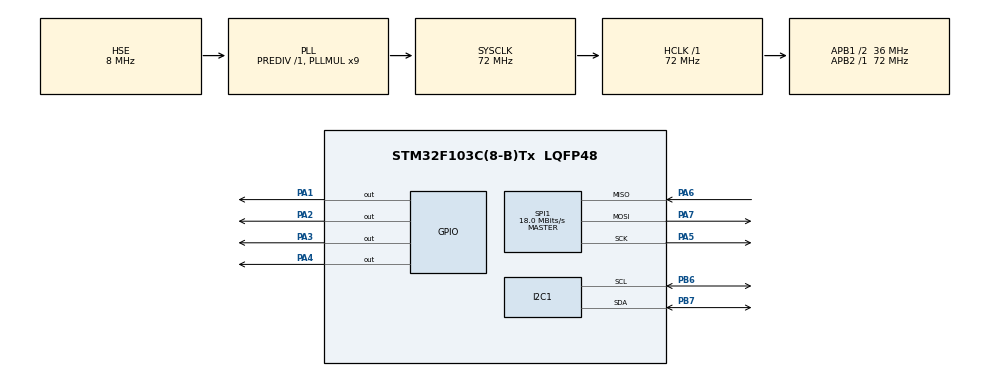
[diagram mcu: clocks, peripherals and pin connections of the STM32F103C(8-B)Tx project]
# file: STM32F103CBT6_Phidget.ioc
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Mcu.Family=STM32F1
Mcu.Name=STM32F103C(8-B)Tx
Mcu.Package=LQFP48
NVIC.I2C1_ER_IRQn=true\:0\:0\:false\:false\:true
NVIC.I2C1_EV_IRQn=true\:0\:0\:false\:false\:true
NVIC.PriorityGroup=NVIC_PRIORITYGROUP_4
NVIC.RCC_IRQn=true\:0\:0\:false\:false\:true
NVIC.RTC_IRQn=true\:0\:0\:false\:false\:true
NVIC.SPI1_IRQn=true\:0\:0\:false\:false\:true
NVIC.TIM1_UP_IRQn=true\:2\:0\:true\:false\:true
NVIC.TIM2_IRQn=true\:2\:0\:true\:false\:true
NVIC.TIM3_IRQn=true\:2\:0\:true\:false\:true
NVIC.TIM4_IRQn=true\:2\:0\:true\:false\:true
PA1.Signal=GPIO_Output
PA13.Mode=Serial_Wire
PA13.Signal=SYS_JTMS-SWDIO
PA14.Mode=Serial_Wire
PA14.Signal=SYS_JTCK-SWCLK
PA2.Signal=GPIO_Output
PA3.Signal=GPIO_Output
PA4.Signal=GPIO_Output
PA5.Mode=Full_Duplex_Master
PA5.Signal=SPI1_SCK
PA6.Mode=Full_Duplex_Master
PA6.Signal=SPI1_MISO
PA7.Mode=Full_Duplex_Master
PA7.Signal=SPI1_MOSI
PB6.Mode=I2C
PB6.Signal=I2C1_SCL
PB7.Mode=I2C
PB7.Signal=I2C1_SDA
PD0-OSC_IN.Mode=HSE-External-Oscillator
PD0-OSC_IN.Signal=RCC_OSC_IN
PD1-OSC_OUT.Mode=HSE-External-Oscillator
PD1-OSC_OUT.Signal=RCC_OSC_OUT
ProjectManager.HeapSize=0x200
ProjectManager.StackSize=0x400
ProjectManager.TargetToolchain=MDK-ARM V5
RCC.AHBFreq_Value=72000000
RCC.APB1CLKDivider=RCC_HCLK_DIV2
RCC.APB1Freq_Value=36000000
RCC.APB1TimFreq_Value=72000000
RCC.APB2Freq_Value=72000000
RCC.APB2TimFreq_Value=72000000
RCC.EnbaleCSS=true
RCC.HCLKFreq_Value=72000000
RCC.HSIState=RCC_HSI_ON
RCC.PLLMUL=RCC_PLL_MUL9
RCC.PLLSourceVirtual=RCC_PLLSOURCE_HSE
RCC.SYSCLKFreq_VALUE=72000000
RCC.SYSCLKSource=RCC_SYSCLKSOURCE_PLLCLK
RCC.USBFreq_Value=72000000
SPI1.BaudRatePrescaler=SPI_BAUDRATEPRESCALER_4
SPI1.CalculateBaudRate=18.0 MBits/s
SPI1.Mode=SPI_MODE_MASTER
TIM1.Period=59999
TIM1.Prescaler=11
TIM2.Period=59999
TIM2.Prescaler=11
TIM3.Period=59999
TIM3.Prescaler=59
TIM4.Period=59999
TIM4.Prescaler=119
VP_RTC_VS_RTC_Activate.Mode=RTC_Enabled
VP_RTC_VS_RTC_Calendar.Mode=RTC_Calendar
VP_TIM1_VS_ClockSourceINT.Mode=Internal
VP_TIM2_VS_ClockSourceINT.Mode=Internal
VP_TIM3_VS_ClockSourceINT.Mode=Internal
VP_TIM4_VS_ClockSourceINT.Mode=Internal
board=STM32F103CBT6_Phidget

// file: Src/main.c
/**
  ******************************************************************************
  * File Name          : main.c
  * Description        : Main program body
  ******************************************************************************
  *
  * COPYRIGHT(c) 2017 STMicroelectronics
  *
  * Redistribution and use in source and binary forms, with or without modification,
  * are permitted provided that the following conditions are met:
  *   1. Redistributions of source code must retain the above copyright notice,
  *      this list of conditions and the following disclaimer.
  *   2. Redistributions in binary form must reproduce the above copyright notice,
  *      this list of conditions and the following disclaimer in the documentation
  *      and/or other materials provided with the distribution.
  *   3. Neither the name of STMicroelectronics nor the names of its contributors
  *      may be used to endorse or promote products derived from this software
  *      without specific prior written permission.
  *
  * THIS SOFTWARE IS PROVIDED BY THE COPYRIGHT HOLDERS AND CONTRIBUTORS "AS IS"
  * AND ANY EXPRESS OR IMPLIED WARRANTIES, INCLUDING, BUT NOT LIMITED TO, THE
  * IMPLIED WARRANTIES OF MERCHANTABILITY AND FITNESS FOR A PARTICULAR PURPOSE ARE
  * DISCLAIMED. IN NO EVENT SHALL THE COPYRIGHT HOLDER OR CONTRIBUTORS BE LIABLE
  * FOR ANY DIRECT, INDIRECT, INCIDENTAL, SPECIAL, EXEMPLARY, OR CONSEQUENTIAL
  * DAMAGES (INCLUDING, BUT NOT LIMITED TO, PROCUREMENT OF SUBSTITUTE GOODS OR
  * SERVICES; LOSS OF USE, DATA, OR PROFITS; OR BUSINESS INTERRUPTION) HOWEVER
  * CAUSED AND ON ANY THEORY OF LIABILITY, WHETHER IN CONTRACT, STRICT LIABILITY,
  * OR TORT (INCLUDING NEGLIGENCE OR OTHERWISE) ARISING IN ANY WAY OUT OF THE USE
  * OF THIS SOFTWARE, EVEN IF ADVISED OF THE POSSIBILITY OF SUCH DAMAGE.
  *
  ******************************************************************************
  */
#include "main.h"
#include "stm32f1xx_hal.h"

I2C_HandleTypeDef hi2c1;

RTC_HandleTypeDef hrtc;

SPI_HandleTypeDef hspi1;

TIM_HandleTypeDef htim1;
TIM_HandleTypeDef htim2;
TIM_HandleTypeDef htim3;
TIM_HandleTypeDef htim4;

/* USER CODE BEGIN PV */
/* Private variables ---------------------------------------------------------*/
extern void APP_Run_StateMachine(void);
extern void HAL_TIM_PeriodElapsedCallback(TIM_HandleTypeDef *htim);

/* USER CODE END PV */

void SystemClock_Config(void);
void Error_Handler(void);
static void MX_GPIO_Init(void);
static void MX_RTC_Init(void);
static void MX_TIM1_Init(void);
static void MX_TIM2_Init(void);
static void MX_TIM3_Init(void);
static void MX_TIM4_Init(void);
static void MX_I2C1_Init(void);
static void MX_SPI1_Init(void);

/* USER CODE BEGIN PFP */
/* Private function prototypes -----------------------------------------------*/

/* USER CODE END PFP */

int main(void)
{

  /* MCU Configuration----------------------------------------------------------*/

  /* Reset of all peripherals, Initializes the Flash interface and the Systick. */
  HAL_Init();

  /* Configure the system clock */
  SystemClock_Config();

  /* Initialize all configured peripherals */
  MX_GPIO_Init();
  MX_RTC_Init();
  MX_TIM1_Init();
  MX_TIM2_Init();
  MX_TIM3_Init();
  MX_TIM4_Init();
  MX_I2C1_Init();
  MX_SPI1_Init();

  /* USER CODE BEGIN 2 */
	HAL_TIM_Base_Start_IT(&htim1);
	HAL_TIM_Base_Start_IT(&htim2);
	HAL_TIM_Base_Start_IT(&htim3);
	HAL_TIM_Base_Start_IT(&htim4);
  /* USER CODE END 2 */

  /* Infinite loop */
  /* USER CODE BEGIN WHILE */
  while (1)
  {
		APP_Run_StateMachine();
  /* USER CODE END WHILE */

  }

}

/** System Clock Configuration
*/
void SystemClock_Config(void)
{

  RCC_OscInitTypeDef RCC_OscInitStruct;
  RCC_ClkInitTypeDef RCC_ClkInitStruct;
  RCC_PeriphCLKInitTypeDef PeriphClkInit;

    /**Initializes the CPU, AHB and APB busses clocks
    */
  RCC_OscInitStruct.OscillatorType = RCC_OSCILLATORTYPE_LSI|RCC_OSCILLATORTYPE_HSE;
  RCC_OscInitStruct.HSEState = RCC_HSE_ON;
  RCC_OscInitStruct.HSEPredivValue = RCC_HSE_PREDIV_DIV1;
  RCC_OscInitStruct.HSIState = RCC_HSI_ON;
  RCC_OscInitStruct.LSIState = RCC_LSI_ON;
  RCC_OscInitStruct.PLL.PLLState = RCC_PLL_ON;
  RCC_OscInitStruct.PLL.PLLSource = RCC_PLLSOURCE_HSE;
  RCC_OscInitStruct.PLL.PLLMUL = RCC_PLL_MUL9;
  if (HAL_RCC_OscConfig(&RCC_OscInitStruct) != HAL_OK)
  {
    Error_Handler();
  }

    /**Initializes the CPU, AHB and APB busses clocks
    */
  RCC_ClkInitStruct.ClockType = RCC_CLOCKTYPE_HCLK|RCC_CLOCKTYPE_SYSCLK
                              |RCC_CLOCKTYPE_PCLK1|RCC_CLOCKTYPE_PCLK2;
  RCC_ClkInitStruct.SYSCLKSource = RCC_SYSCLKSOURCE_PLLCLK;
  RCC_ClkInitStruct.AHBCLKDivider = RCC_SYSCLK_DIV1;
  RCC_ClkInitStruct.APB1CLKDivider = RCC_HCLK_DIV2;
  RCC_ClkInitStruct.APB2CLKDivider = RCC_HCLK_DIV1;

  if (HAL_RCC_ClockConfig(&RCC_ClkInitStruct, FLASH_LATENCY_2) != HAL_OK)
  {
    Error_Handler();
  }

  PeriphClkInit.PeriphClockSelection = RCC_PERIPHCLK_RTC;
  PeriphClkInit.RTCClockSelection = RCC_RTCCLKSOURCE_LSI;
  if (HAL_RCCEx_PeriphCLKConfig(&PeriphClkInit) != HAL_OK)
  {
    Error_Handler();
  }

    /**Enables the Clock Security System
    */
  HAL_RCC_EnableCSS();

    /**Configure the Systick interrupt time
    */
  HAL_SYSTICK_Config(HAL_RCC_GetHCLKFreq()/1000);

    /**Configure the Systick
    */
  HAL_SYSTICK_CLKSourceConfig(SYSTICK_CLKSOURCE_HCLK);

  /* SysTick_IRQn interrupt configuration */
  HAL_NVIC_SetPriority(SysTick_IRQn, 0, 0);
}

/* I2C1 init function */
static void MX_I2C1_Init(void)
{

  hi2c1.Instance = I2C1;
  hi2c1.Init.ClockSpeed = 100000;
  hi2c1.Init.DutyCycle = I2C_DUTYCYCLE_2;
  hi2c1.Init.OwnAddress1 = 0;
  hi2c1.Init.AddressingMode = I2C_ADDRESSINGMODE_7BIT;
  hi2c1.Init.DualAddressMode = I2C_DUALADDRESS_DISABLE;
  hi2c1.Init.OwnAddress2 = 0;
  hi2c1.Init.GeneralCallMode = I2C_GENERALCALL_DISABLE;
  hi2c1.Init.NoStretchMode = I2C_NOSTRETCH_DISABLE;
  if (HAL_I2C_Init(&hi2c1) != HAL_OK)
  {
    Error_Handler();
  }

}

/* RTC init function */
static void MX_RTC_Init(void)
{

  RTC_TimeTypeDef sTime;
  RTC_DateTypeDef DateToUpdate;

    /**Initialize RTC Only
    */
  hrtc.Instance = RTC;
  hrtc.Init.AsynchPrediv = RTC_AUTO_1_SECOND;
  hrtc.Init.OutPut = RTC_OUTPUTSOURCE_ALARM;
  if (HAL_RTC_Init(&hrtc) != HAL_OK)
  {
    Error_Handler();
  }

    /**Initialize RTC and set the Time and Date
    */
  sTime.Hours = 0x1;
  sTime.Minutes = 0x0;
  sTime.Seconds = 0x0;

  if (HAL_RTC_SetTime(&hrtc, &sTime, RTC_FORMAT_BCD) != HAL_OK)
  {
    Error_Handler();
  }

  DateToUpdate.WeekDay = RTC_WEEKDAY_MONDAY;
  DateToUpdate.Month = RTC_MONTH_JANUARY;
  DateToUpdate.Date = 0x1;
  DateToUpdate.Year = 0x0;

  if (HAL_RTC_SetDate(&hrtc, &DateToUpdate, RTC_FORMAT_BCD) != HAL_OK)
  {
    Error_Handler();
  }

}

/* SPI1 init function */
static void MX_SPI1_Init(void)
{

  hspi1.Instance = SPI1;
  hspi1.Init.Mode = SPI_MODE_MASTER;
  hspi1.Init.Direction = SPI_DIRECTION_2LINES;
  hspi1.Init.DataSize = SPI_DATASIZE_8BIT;
  hspi1.Init.CLKPolarity = SPI_POLARITY_LOW;
  hspi1.Init.CLKPhase = SPI_PHASE_1EDGE;
  hspi1.Init.NSS = SPI_NSS_SOFT;
  hspi1.Init.BaudRatePrescaler = SPI_BAUDRATEPRESCALER_4;
  hspi1.Init.FirstBit = SPI_FIRSTBIT_MSB;
  hspi1.Init.TIMode = SPI_TIMODE_DISABLE;
  hspi1.Init.CRCCalculation = SPI_CRCCALCULATION_DISABLE;
  hspi1.Init.CRCPolynomial = 10;
  if (HAL_SPI_Init(&hspi1) != HAL_OK)
  {
    Error_Handler();
  }

}

/* TIM1 init function */
static void MX_TIM1_Init(void)
{

  TIM_ClockConfigTypeDef sClockSourceConfig;
  TIM_MasterConfigTypeDef sMasterConfig;

  htim1.Instance = TIM1;
  htim1.Init.Prescaler = 11;
  htim1.Init.CounterMode = TIM_COUNTERMODE_UP;
  htim1.Init.Period = 59999;
  htim1.Init.ClockDivision = TIM_CLOCKDIVISION_DIV1;
  htim1.Init.RepetitionCounter = 0;
  if (HAL_TIM_Base_Init(&htim1) != HAL_OK)
  {
    Error_Handler();
  }

  sClockSourceConfig.ClockSource = TIM_CLOCKSOURCE_INTERNAL;
  if (HAL_TIM_ConfigClockSource(&htim1, &sClockSourceConfig) != HAL_OK)
  {
    Error_Handler();
  }

  sMasterConfig.MasterOutputTrigger = TIM_TRGO_RESET;
  sMasterConfig.MasterSlaveMode = TIM_MASTERSLAVEMODE_DISABLE;
  if (HAL_TIMEx_MasterConfigSynchronization(&htim1, &sMasterConfig) != HAL_OK)
  {
    Error_Handler();
  }

}

/* TIM2 init function */
static void MX_TIM2_Init(void)
{

  TIM_ClockConfigTypeDef sClockSourceConfig;
  TIM_MasterConfigTypeDef sMasterConfig;

  htim2.Instance = TIM2;
  htim2.Init.Prescaler = 11;
  htim2.Init.CounterMode = TIM_COUNTERMODE_UP;
  htim2.Init.Period = 59999;
  htim2.Init.ClockDivision = TIM_CLOCKDIVISION_DIV1;
  if (HAL_TIM_Base_Init(&htim2) != HAL_OK)
  {
    Error_Handler();
  }

  sClockSourceConfig.ClockSource = TIM_CLOCKSOURCE_INTERNAL;
  if (HAL_TIM_ConfigClockSource(&htim2, &sClockSourceConfig) != HAL_OK)
  {
    Error_Handler();
  }

  sMasterConfig.MasterOutputTrigger = TIM_TRGO_RESET;
  sMasterConfig.MasterSlaveMode = TIM_MASTERSLAVEMODE_DISABLE;
  if (HAL_TIMEx_MasterConfigSynchronization(&htim2, &sMasterConfig) != HAL_OK)
  {
    Error_Handler();
  }

}

/* TIM3 init function */
static void MX_TIM3_Init(void)
{

  TIM_ClockConfigTypeDef sClockSourceConfig;
  TIM_MasterConfigTypeDef sMasterConfig;

  htim3.Instance = TIM3;
  htim3.Init.Prescaler = 59;
  htim3.Init.CounterMode = TIM_COUNTERMODE_UP;
  htim3.Init.Period = 59999;
  htim3.Init.ClockDivision = TIM_CLOCKDIVISION_DIV1;
  if (HAL_TIM_Base_Init(&htim3) != HAL_OK)
  {
    Error_Handler();
  }

  sClockSourceConfig.ClockSource = TIM_CLOCKSOURCE_INTERNAL;
  if (HAL_TIM_ConfigClockSource(&htim3, &sClockSourceConfig) != HAL_OK)
  {
    Error_Handler();
  }

  sMasterConfig.MasterOutputTrigger = TIM_TRGO_RESET;
  sMasterConfig.MasterSlaveMode = TIM_MASTERSLAVEMODE_DISABLE;
  if (HAL_TIMEx_MasterConfigSynchronization(&htim3, &sMasterConfig) != HAL_OK)
  {
    Error_Handler();
  }

}

/* TIM4 init function */
static void MX_TIM4_Init(void)
{

  TIM_ClockConfigTypeDef sClockSourceConfig;
  TIM_MasterConfigTypeDef sMasterConfig;

  htim4.Instance = TIM4;
  htim4.Init.Prescaler = 119;
  htim4.Init.CounterMode = TIM_COUNTERMODE_UP;
  htim4.Init.Period = 59999;
  htim4.Init.ClockDivision = TIM_CLOCKDIVISION_DIV1;
  if (HAL_TIM_Base_Init(&htim4) != HAL_OK)
  {
    Error_Handler();
  }

  sClockSourceConfig.ClockSource = TIM_CLOCKSOURCE_INTERNAL;
  if (HAL_TIM_ConfigClockSource(&htim4, &sClockSourceConfig) != HAL_OK)
  {
    Error_Handler();
  }

  sMasterConfig.MasterOutputTrigger = TIM_TRGO_RESET;
  sMasterConfig.MasterSlaveMode = TIM_MASTERSLAVEMODE_DISABLE;
  if (HAL_TIMEx_MasterConfigSynchronization(&htim4, &sMasterConfig) != HAL_OK)
  {
    Error_Handler();
  }

}

/** Configure pins as
        * Analog
        * Input
        * Output
        * EVENT_OUT
        * EXTI
*/
static void MX_GPIO_Init(void)
{

  GPIO_InitTypeDef GPIO_InitStruct;

  /* GPIO Ports Clock Enable */
  __HAL_RCC_GPIOD_CLK_ENABLE();
  __HAL_RCC_GPIOA_CLK_ENABLE();
  __HAL_RCC_GPIOB_CLK_ENABLE();

  /*Configure GPIO pin Output Level */
  HAL_GPIO_WritePin(GPIOA, GPIO_PIN_1|GPIO_PIN_2|GPIO_PIN_3|GPIO_PIN_4, GPIO_PIN_RESET);

  /*Configure GPIO pins : PA1 PA2 PA3 PA4 */
  GPIO_InitStruct.Pin = GPIO_PIN_1|GPIO_PIN_2|GPIO_PIN_3|GPIO_PIN_4;
  GPIO_InitStruct.Mode = GPIO_MODE_OUTPUT_PP;
  GPIO_InitStruct.Speed = GPIO_SPEED_FREQ_LOW;
  HAL_GPIO_Init(GPIOA, &GPIO_InitStruct);

}

void Error_Handler(void)
{
  while(1)
  {
  }
}

/************************ (C) COPYRIGHT STMicroelectronics *****END OF FILE****/
